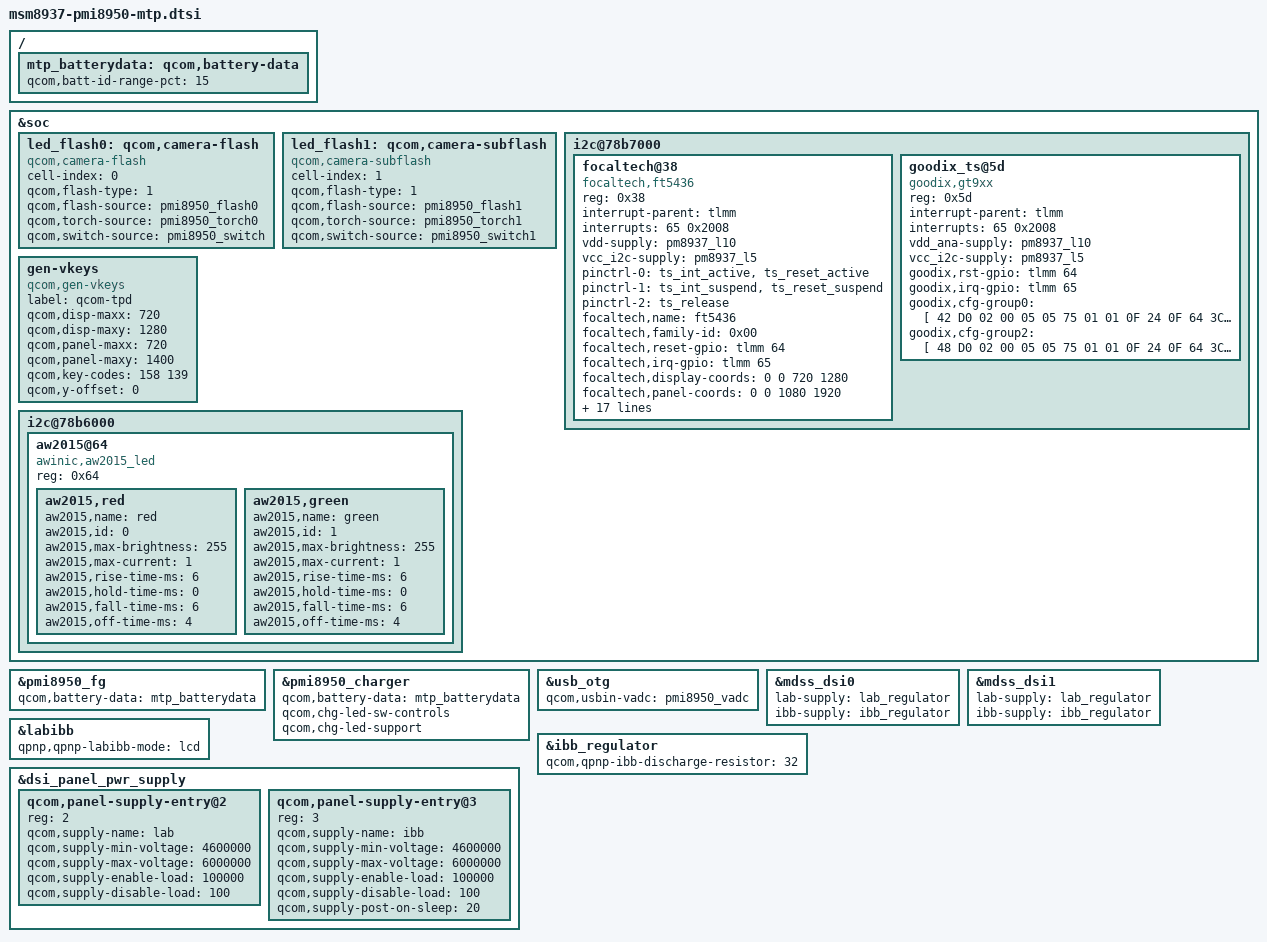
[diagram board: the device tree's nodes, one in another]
/*
 * Copyright (c) 2015-2016, The Linux Foundation. All rights reserved.
 *
 * This program is free software; you can redistribute it and/or modify
 * it under the terms of the GNU General Public License version 2 and
 * only version 2 as published by the Free Software Foundation.
 *
 * This program is distributed in the hope that it will be useful,
 * but WITHOUT ANY WARRANTY; without even the implied warranty of
 * MERCHANTABILITY or FITNESS FOR A PARTICULAR PURPOSE.  See the
 * GNU General Public License for more details.
 */

#include "msm-pmi8950.dtsi"
#include "msm8937-mtp.dtsi"
#include "msm8937-audio-mtp.dtsi"

&soc {
	led_flash0: qcom,camera-flash {
		cell-index = <0>;
		compatible = "qcom,camera-flash";
		qcom,flash-type = <1>;
		qcom,flash-source = <&pmi8950_flash0>;
		qcom,torch-source = <&pmi8950_torch0>;
		qcom,switch-source = <&pmi8950_switch>;
	};
    led_flash1: qcom,camera-subflash {
		cell-index = <1>;
		compatible = "qcom,camera-subflash";
		qcom,flash-type = <1>;
		qcom,flash-source = <&pmi8950_flash1>;
		qcom,torch-source = <&pmi8950_torch1>;
		qcom,switch-source = <&pmi8950_switch1>;
	};
	/* wangs: add TP i2c_3 */
	i2c@78b7000 {
		status = "ok";

		focaltech@38 {
		    compatible = "focaltech,ft5436";
		    reg = <0x38>;
		    interrupt-parent = <&tlmm>;
		    interrupts = <65 0x2008>;
		    vdd-supply = <&pm8937_l10>;
		    vcc_i2c-supply = <&pm8937_l5>;
		    /* pins used by touchscreen */
		    pinctrl-names = "pmx_ts_active",
			"pmx_ts_suspend",
			"pmx_ts_release";
		    pinctrl-0 = <&ts_int_active &ts_reset_active>;
		    pinctrl-1 = <&ts_int_suspend &ts_reset_suspend>;
		    pinctrl-2 = <&ts_release>;
		    focaltech,name = "ft5436";
		    focaltech,family-id = <0x00>;
		    focaltech,reset-gpio = <&tlmm 64 0x0>;
		    focaltech,irq-gpio = <&tlmm 65 0x0>;
		    focaltech,display-coords = <0 0 720 1280>;
		    focaltech,panel-coords = <0 0 1080 1920>;
		    focaltech,button-map= <139 172 158>;
		    focaltech,no-force-update;
		    focaltech,i2c-pull-up;
		    focaltech,group-id = <1>;
		    focaltech,hard-reset-delay-ms = <20>;
		    focaltech,soft-reset-delay-ms = <200>;
		    focaltech,num-max-touches = <10>;
		    focaltech,fw-delay-aa-ms = <30>;
		    focaltech,fw-delay-55-ms = <30>;
		    focaltech,fw-upgrade-id1 = <0x79>;
		    focaltech,fw-upgrade-id2 = <0x08>;
		    focaltech,fw-delay-readid-ms = <10>;
		    focaltech,fw-delay-era-flsh-ms = <2000>;
		    focaltech,fw-auto-cal;
		    focaltech,ignore-id-check;
		    /* Underlying clocks used by secure touch */
		    clock-names = "iface_clk", "core_clk";
		    clocks = <&clock_gcc clk_gcc_blsp1_ahb_clk>,
			   <&clock_gcc clk_gcc_blsp1_qup3_i2c_apps_clk>;
		};

		goodix_ts@5d {
			compatible = "goodix,gt9xx";
			reg = <0x5d>;
			interrupt-parent = <&tlmm>;
			interrupts = <65 0x2008>;
			vdd_ana-supply = <&pm8937_l10>;
			vcc_i2c-supply = <&pm8937_l5>;
			goodix,rst-gpio = <&tlmm 64 0x0>;
			goodix,irq-gpio = <&tlmm 65 0x0>;
			goodix,cfg-group0 = [
				42 D0 02 00 05 05 75 01 01 0F 24
				0F 64 3C 03 05 00 00 00 02 00 00
				00 16 19 1C 14 8C 0E 0E 24 00 31
				0D 00 00 00 83 33 1D 00 41 00 00
				00 00 00 08 0A 00 2B 1C 3C 94 D5
				03 08 00 00 04 93 1E 00 82 23 00
				74 29 00 69 2F 00 5F 37 00 5F 20
				40 60 00 F0 40 30 55 50 27 00 00
				00 00 00 00 00 00 00 00 00 00 00
				00 00 00 00 00 00 00 14 19 00 00
				50 50 02 04 06 08 0A 0C 0E 10 12
				14 16 18 1A 1C 00 00 00 00 00 00
				00 00 00 00 00 00 00 00 00 00 1D
				1E 1F 20 21 22 24 26 28 29 2A 1C
				18 16 14 13 12 10 0F 0C 0A 08 06
				04 02 00 00 00 00 00 00 00 00 00
				00 00 00 00 00 00 00 00 9C 01];
			goodix,cfg-group2 = [
				48 D0 02 00 05 05 75 01 01 0F 24
				0F 64 3C 03 05 00 00 00 02 00 00
				00 16 19 1C 14 8C 0E 0E 24 00 31
				0D 00 00 00 83 33 1D 00 41 00 00
				3C 0A 14 08 0A 00 2B 1C 3C 94 D5
				03 08 00 00 04 93 1E 00 82 23 00
				74 29 00 69 2F 00 5F 37 00 5F 20
				40 60 00 F0 40 30 55 50 27 00 00
				00 00 00 00 00 00 00 00 00 00 00
				00 00 00 00 00 00 00 14 19 00 00
				50 50 02 04 06 08 0A 0C 0E 10 12
				14 16 18 1A 1C 00 00 00 00 00 00
				00 00 00 00 00 00 00 00 00 00 1D
				1E 1F 20 21 22 24 26 28 29 2A 1C
				18 16 14 13 12 10 0F 0C 0A 08 06
				04 02 00 00 00 00 00 00 00 00 00
				00 00 00 00 00 00 00 00 3C 01];
		};
	};

	gen-vkeys {
		compatible = "qcom,gen-vkeys";
		label = "qcom-tpd";
		qcom,disp-maxx = <720>;
		qcom,disp-maxy = <1280>;
		qcom,panel-maxx = <720>;
		qcom,panel-maxy = <1400>;
		qcom,key-codes = <158 139>;
		qcom,y-offset = <0>;
	};

	i2c@78b6000 {
		status = "ok";

		aw2015@64 {
			compatible = "awinic,aw2015_led";
			reg = <0x64>;
			aw2015,red {
				aw2015,name = "red";
				aw2015,id = <0>;
				aw2015,max-brightness = <255>;
				aw2015,max-current = <1>;
				aw2015,rise-time-ms = <6>;
				aw2015,hold-time-ms = <0>;
				aw2015,fall-time-ms = <6>;
				aw2015,off-time-ms = <4>;
			};

			aw2015,green {
				aw2015,name = "green";
				aw2015,id = <1>;
				aw2015,max-brightness = <255>;
				aw2015,max-current = <1>;
				aw2015,rise-time-ms = <6>;
				aw2015,hold-time-ms = <0>;
				aw2015,fall-time-ms = <6>;
				aw2015,off-time-ms = <4>;
			};
		};
	};
};

/{
	mtp_batterydata: qcom,battery-data {
		qcom,batt-id-range-pct = <15>;
		#include "batterydata-asus1516-5000mah-1st.dtsi"
		#include "batterydata-asus1526-4120mah-1st.dtsi"
		#include "batterydata-asus1516-5000mah-2nd.dtsi" /* this one is unused because the BATT-ID value is same as before (1st) */
		//#include "batterydata-itech-3000mah.dtsi"
		//#include "batterydata-ascent-3450mAh.dtsi"
		//#include "batterydata_Asus_4850mAh.dtsi"
	};
};

&pmi8950_fg {
	qcom,battery-data = <&mtp_batterydata>;
};

&pmi8950_charger {
	qcom,battery-data = <&mtp_batterydata>;
	qcom,chg-led-sw-controls;
	qcom,chg-led-support;
};

&usb_otg {
	qcom,usbin-vadc = <&pmi8950_vadc>;
};

&mdss_dsi0 {
	lab-supply = <&lab_regulator>;
	ibb-supply = <&ibb_regulator>;
};

&mdss_dsi1 {
	lab-supply = <&lab_regulator>;
	ibb-supply = <&ibb_regulator>;
};

&labibb {
	status = "ok";
	qpnp,qpnp-labibb-mode = "lcd";
};

&ibb_regulator {
	qcom,qpnp-ibb-discharge-resistor = <32>;
};

&dsi_panel_pwr_supply {
	qcom,panel-supply-entry@2 {
		reg = <2>;
		qcom,supply-name = "lab";
		qcom,supply-min-voltage = <4600000>;
		qcom,supply-max-voltage = <6000000>;
		qcom,supply-enable-load = <100000>;
		qcom,supply-disable-load = <100>;
	};

	qcom,panel-supply-entry@3 {
		reg = <3>;
		qcom,supply-name = "ibb";
		qcom,supply-min-voltage = <4600000>;
		qcom,supply-max-voltage = <6000000>;
		qcom,supply-enable-load = <100000>;
		qcom,supply-disable-load = <100>;
		qcom,supply-post-on-sleep = <20>;
	};
};
